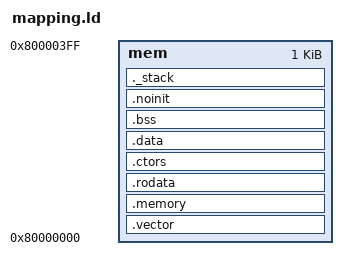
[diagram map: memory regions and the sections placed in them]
/*
This is free and unencumbered software released into the public domain.

Anyone is free to copy, modify, publish, use, compile, sell, or
distribute this software, either in source code form or as a compiled
binary, for any purpose, commercial or non-commercial, and by any
means.
*/
OUTPUT_FORMAT("elf32-littleriscv", "elf32-littleriscv", "elf32-littleriscv")
OUTPUT_ARCH(riscv)
ENTRY(crtStart)

MEMORY {
  mem : ORIGIN = 0x80000000, LENGTH = 0x00000400
}

_stack_size = DEFINED(_stack_size) ? _stack_size : 0;

SECTIONS {

  .vector : {
    *crt.o(.text);
  } > mem

  .memory : {
    *(.text);
    end = .;
  } > mem

  .rodata         :
  {
    *(.rdata)
    *(.rodata .rodata.*)
    *(.gnu.linkonce.r.*)
  } > mem

  .ctors          :
  {
    . = ALIGN(4);
    _ctors_start = .;
    KEEP(*(.init_array*))
    KEEP (*(SORT(.ctors.*)))
    KEEP (*(.ctors))
    . = ALIGN(4);
    _ctors_end = .;
  } > mem

  .data          :
  {
    *(.rdata)
    *(.rodata .rodata.*)
    *(.gnu.linkonce.r.*)
    *(.data .data.*)
    *(.gnu.linkonce.d.*)
    . = ALIGN(8);
    PROVIDE( __global_pointer$ = . + 0x800 );
    *(.sdata .sdata.*)
    *(.gnu.linkonce.s.*)
    . = ALIGN(8);
    *(.srodata.cst16)
    *(.srodata.cst8)
    *(.srodata.cst4)
    *(.srodata.cst2)
    *(.srodata .srodata.*)
  } > mem

  .bss (NOLOAD) : {
		. = ALIGN(4);
		/* This is used by the startup in order to initialize the .bss secion */
		_bss_start = .;
    *(.sbss*)
    *(.gnu.linkonce.sb.*)
    *(.bss .bss.*)
    *(.gnu.linkonce.b.*)
    *(COMMON)
		. = ALIGN(4);
		_bss_end = .;
  } > mem

  .noinit (NOLOAD) : {
      . = ALIGN(4);
      *(.noinit .noinit.*)
      . = ALIGN(4);
  } > mem

  ._stack (NOLOAD):
  {
    . = ALIGN(16);
    PROVIDE (_stack_end = .);
    . = . + _stack_size;
    . = ALIGN(16);
    PROVIDE (_stack_start = .);
  } > mem

}

